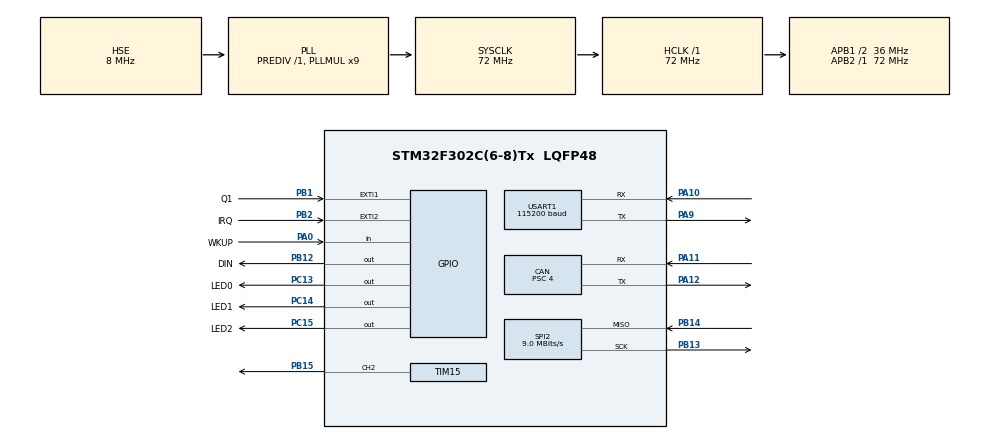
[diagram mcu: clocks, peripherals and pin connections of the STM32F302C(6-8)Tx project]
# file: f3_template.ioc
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CAN.BS1=CAN_BS1_4TQ
CAN.BS2=CAN_BS2_4TQ
CAN.CalculateBaudRate=1000000
CAN.CalculateTimeBit=1000
CAN.CalculateTimeQuantum=111.11111111111111
CAN.NART=DISABLE
CAN.Prescaler=4
CAN.RFLM=DISABLE
CAN.SJW=CAN_SJW_1TQ
Mcu.Family=STM32F3
Mcu.Name=STM32F302C(6-8)Tx
Mcu.Package=LQFP48
NVIC.EXTI2_TSC_IRQn=true\:0\:0\:true\:false\:true\:true\:true\:true
NVIC.PriorityGroup=NVIC_PRIORITYGROUP_4
NVIC.USART1_IRQn=true\:0\:0\:true\:false\:true\:true\:true\:true
PA0.GPIO_Label=WKUP
PA0.GPIO_PuPd=GPIO_PULLUP
PA0.Signal=GPIO_Input
PA10.GPIO_PuPd=GPIO_NOPULL
PA10.Mode=Asynchronous
PA10.Signal=USART1_RX
PA11.GPIO_PuPd=GPIO_PULLUP
PA11.Mode=CAN_Activate
PA11.Signal=CAN_RX
PA12.GPIO_PuPd=GPIO_PULLUP
PA12.Mode=CAN_Activate
PA12.Signal=CAN_TX
PA13.Mode=JTAG_5_pins
PA13.Signal=SYS_JTMS-SWDIO
PA14.Mode=JTAG_5_pins
PA14.Signal=SYS_JTCK-SWCLK
PA15.Mode=JTAG_5_pins
PA15.Signal=SYS_JTDI
PA9.GPIO_PuPd=GPIO_NOPULL
PA9.Mode=Asynchronous
PA9.Signal=USART1_TX
PB1.GPIO_Label=Q1
PB1.Signal=GPXTI1
PB12.GPIO_Label=DIN
PB12.GPIO_PuPd=GPIO_PULLUP
PB12.GPIO_Speed=GPIO_SPEED_FREQ_HIGH
PB12.Signal=GPIO_Output
PB13.GPIO_PuPd=GPIO_PULLUP
PB13.Mode=RX_Only_Simplex_Unidirect_Master
PB13.Signal=SPI2_SCK
PB14.GPIO_PuPd=GPIO_PULLUP
PB14.Mode=RX_Only_Simplex_Unidirect_Master
PB14.Signal=SPI2_MISO
PB15.Signal=S_TIM15_CH2
PB2.GPIO_Label=IRQ
PB2.GPIO_ModeDefaultEXTI=GPIO_MODE_IT_FALLING
PB2.Signal=GPXTI2
PB3.Mode=JTAG_5_pins
PB3.Signal=SYS_JTDO-TRACESWO
PB4.Mode=JTAG_5_pins
PB4.Signal=SYS_NJTRST
PC13.GPIO_Label=LED0
PC13.Signal=GPIO_Output
PC14\ -\ OSC32_IN.GPIO_Label=LED1
PC14\ -\ OSC32_IN.Signal=GPIO_Output
PC15\ -\ OSC32_OUT.GPIO_Label=LED2
PC15\ -\ OSC32_OUT.Signal=GPIO_Output
PF0-OSC_IN.Mode=HSE-External-Oscillator
PF0-OSC_IN.Signal=RCC_OSC_IN
PF1-OSC_OUT.Mode=HSE-External-Oscillator
PF1-OSC_OUT.Signal=RCC_OSC_OUT
ProjectManager.HeapSize=0x200
ProjectManager.StackSize=0x400
ProjectManager.TargetToolchain=MDK-ARM V5.32
RCC.ADCFreq_Value=36000000
RCC.AHBFreq_Value=72000000
RCC.APB1CLKDivider=RCC_HCLK_DIV2
RCC.APB1Freq_Value=36000000
RCC.APB1TimFreq_Value=72000000
RCC.APB2CLKDivider=RCC_HCLK_DIV1
RCC.APB2Freq_Value=72000000
RCC.APB2TimFreq_Value=72000000
RCC.CortexFreq_Value=72000000
RCC.HCLKFreq_Value=72000000
RCC.HSE_VALUE=8000000
RCC.HSI_VALUE=8000000
RCC.LSE_VALUE=32768
RCC.PLLMUL=RCC_PLL_MUL9
RCC.PLLSourceVirtual=RCC_PLLSOURCE_HSE
RCC.PREDIV=RCC_PREDIV_DIV1
RCC.SYSCLKFreq_VALUE=72000000
RCC.SYSCLKSourceVirtual=RCC_SYSCLKSOURCE_PLLCLK
RCC.USBFreq_Value=72000000
SH.S_TIM15_CH2.0=TIM15_CH2,PWM Generation2 CH2
SPI2.BaudRatePrescaler=SPI_BAUDRATEPRESCALER_4
SPI2.CalculateBaudRate=9.0 MBits/s
SPI2.DataSize=SPI_DATASIZE_8BIT
SPI2.Direction=SPI_DIRECTION_2LINES_RXONLY
SPI2.Mode=SPI_MODE_MASTER
SPI2.VirtualType=VM_MASTER
TIM15.Channel-PWM\ Generation2\ CH2=TIM_CHANNEL_2
TIM15.OC2Preload_PWM=DISABLE
TIM15.Period=1079
USART1.BaudRate=115200
USART1.VirtualMode=VM_ASYNC
USART1.VirtualMode-Asynchronous=VM_ASYNC
board=custom

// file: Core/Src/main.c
/* USER CODE BEGIN Header */
/**
  ******************************************************************************
  * @file           : main.c
  * @brief          : Main program body
  ******************************************************************************
  * @attention
  *
  * Copyright (c) 2026 STMicroelectronics.
  * All rights reserved.
  *
  * This software is licensed under terms that can be found in the LICENSE file
  * in the root directory of this software component.
  * If no LICENSE file comes with this software, it is provided AS-IS.
  *
  ******************************************************************************
  */
/* USER CODE END Header */
#include "main.h"
#include "can.h"
#include "spi.h"
#include "tim.h"
#include "usart.h"
#include "gpio.h"

/* USER CODE BEGIN Includes */

#include <bsp.h>

/* USER CODE END Includes */

void SystemClock_Config(void);

/* USER CODE BEGIN 0 */
extern void my_task(void);
/* USER CODE END 0 */

int main(void)
{

  /* MCU Configuration--------------------------------------------------------*/

  /* Reset of all peripherals, Initializes the Flash interface and the Systick. */
  HAL_Init();

  /* Configure the system clock */
  SystemClock_Config();

  /* USER CODE BEGIN SysInit */
  delay_init(72);
  /* USER CODE END SysInit */

  /* Initialize all configured peripherals */
  MX_GPIO_Init();
  MX_USART1_UART_Init();
  MX_CAN_Init();
  MX_TIM15_Init();
  MX_SPI2_Init();
  /* USER CODE BEGIN 2 */
  my_task();
  /* USER CODE END 2 */

  /* Infinite loop */
  /* USER CODE BEGIN WHILE */
#if 0
  while (1)
  {
    /* USER CODE END WHILE */

    /* USER CODE BEGIN 3 */
  }
#endif
  /* USER CODE END 3 */
}

void SystemClock_Config(void)
{
  RCC_OscInitTypeDef RCC_OscInitStruct = {0};
  RCC_ClkInitTypeDef RCC_ClkInitStruct = {0};
  RCC_PeriphCLKInitTypeDef PeriphClkInit = {0};

  /** Initializes the RCC Oscillators according to the specified parameters
  * in the RCC_OscInitTypeDef structure.
  */
  RCC_OscInitStruct.OscillatorType = RCC_OSCILLATORTYPE_HSE;
  RCC_OscInitStruct.HSEState = RCC_HSE_ON;
  RCC_OscInitStruct.HSEPredivValue = RCC_HSE_PREDIV_DIV1;
  RCC_OscInitStruct.HSIState = RCC_HSI_ON;
  RCC_OscInitStruct.PLL.PLLState = RCC_PLL_ON;
  RCC_OscInitStruct.PLL.PLLSource = RCC_PLLSOURCE_HSE;
  RCC_OscInitStruct.PLL.PLLMUL = RCC_PLL_MUL9;
  if (HAL_RCC_OscConfig(&RCC_OscInitStruct) != HAL_OK)
  {
    Error_Handler();
  }

  /** Initializes the CPU, AHB and APB buses clocks
  */
  RCC_ClkInitStruct.ClockType = RCC_CLOCKTYPE_HCLK|RCC_CLOCKTYPE_SYSCLK
                              |RCC_CLOCKTYPE_PCLK1|RCC_CLOCKTYPE_PCLK2;
  RCC_ClkInitStruct.SYSCLKSource = RCC_SYSCLKSOURCE_PLLCLK;
  RCC_ClkInitStruct.AHBCLKDivider = RCC_SYSCLK_DIV1;
  RCC_ClkInitStruct.APB1CLKDivider = RCC_HCLK_DIV2;
  RCC_ClkInitStruct.APB2CLKDivider = RCC_HCLK_DIV1;

  if (HAL_RCC_ClockConfig(&RCC_ClkInitStruct, FLASH_LATENCY_2) != HAL_OK)
  {
    Error_Handler();
  }
  PeriphClkInit.PeriphClockSelection = RCC_PERIPHCLK_USART1|RCC_PERIPHCLK_TIM15;
  PeriphClkInit.Usart1ClockSelection = RCC_USART1CLKSOURCE_PCLK1;
  PeriphClkInit.Tim15ClockSelection = RCC_TIM15CLK_HCLK;
  if (HAL_RCCEx_PeriphCLKConfig(&PeriphClkInit) != HAL_OK)
  {
    Error_Handler();
  }
}

void Error_Handler(void)
{
  __disable_irq();
  while (1)
  {
  }
}
